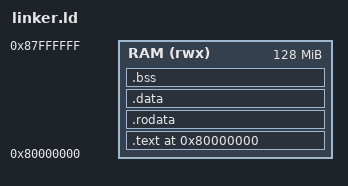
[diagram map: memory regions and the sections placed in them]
/* Linker script for RISC-V 32-bit bare-metal */

OUTPUT_ARCH(riscv)
ENTRY(_start)

MEMORY
{
    RAM (rwx) : ORIGIN = 0x80000000, LENGTH = 128M
}

SECTIONS
{
    . = 0x80000000;
    
    .text : {
        *(.text.start)
        *(.text*)
    } > RAM
    
    .rodata : {
        *(.rodata*)
    } > RAM
    
    .data : {
        *(.data*)
    } > RAM
    
    .bss : {
        *(.bss*)
        *(COMMON)
    } > RAM
    
    . = ALIGN(8);
    _end = .;
}
